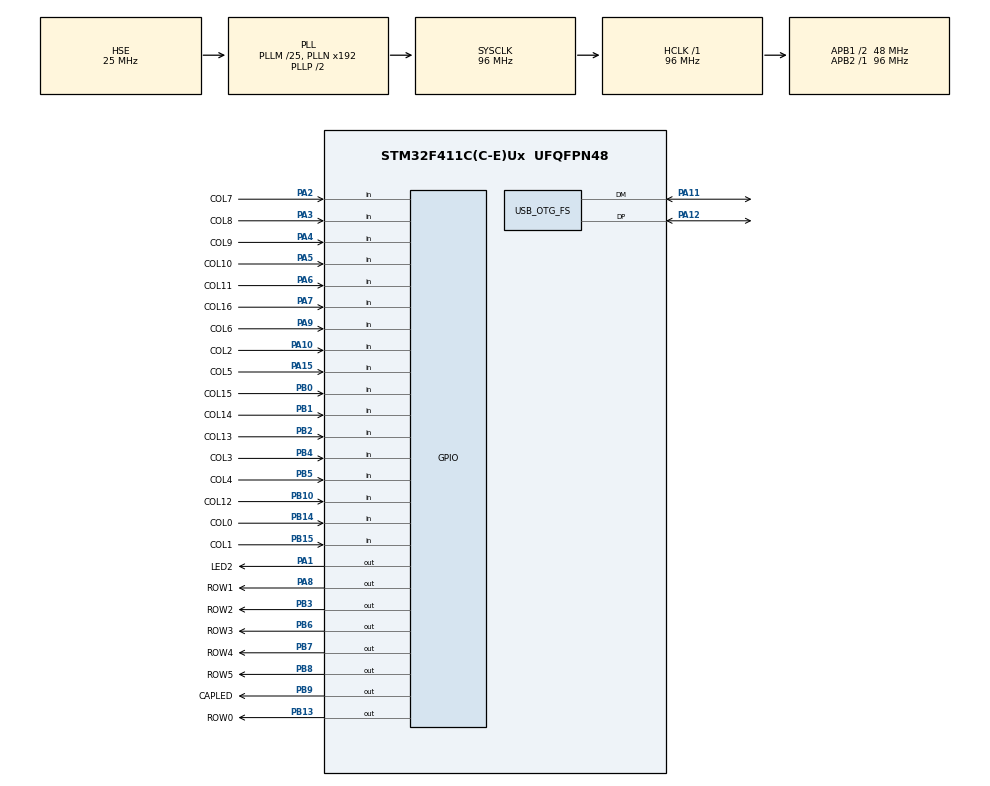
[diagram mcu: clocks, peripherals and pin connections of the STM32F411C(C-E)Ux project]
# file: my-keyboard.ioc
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Mcu.Family=STM32F4
Mcu.Name=STM32F411C(C-E)Ux
Mcu.Package=UFQFPN48
NVIC.OTG_FS_IRQn=true\:0\:0\:false\:false\:true\:false\:true
NVIC.PriorityGroup=NVIC_PRIORITYGROUP_4
PA1.GPIO_Label=LED2
PA1.GPIO_PuPd=GPIO_PULLDOWN
PA1.Signal=GPIO_Output
PA10.GPIO_Label=COL2
PA10.GPIO_PuPd=GPIO_PULLDOWN
PA10.Signal=GPIO_Input
PA11.Mode=Device_Only
PA11.Signal=USB_OTG_FS_DM
PA12.Mode=Device_Only
PA12.Signal=USB_OTG_FS_DP
PA13.Mode=Serial_Wire
PA13.Signal=SYS_JTMS-SWDIO
PA14.Mode=Serial_Wire
PA14.Signal=SYS_JTCK-SWCLK
PA15.GPIO_Label=COL5
PA15.GPIO_PuPd=GPIO_PULLDOWN
PA15.Signal=GPIO_Input
PA2.GPIO_Label=COL7
PA2.GPIO_PuPd=GPIO_PULLDOWN
PA2.Signal=GPIO_Input
PA3.GPIO_Label=COL8
PA3.GPIO_PuPd=GPIO_PULLDOWN
PA3.Signal=GPIO_Input
PA4.GPIO_Label=COL9
PA4.GPIO_PuPd=GPIO_PULLDOWN
PA4.Signal=GPIO_Input
PA5.GPIO_Label=COL10
PA5.GPIO_PuPd=GPIO_PULLDOWN
PA5.Signal=GPIO_Input
PA6.GPIO_Label=COL11
PA6.GPIO_PuPd=GPIO_PULLDOWN
PA6.Signal=GPIO_Input
PA7.GPIO_Label=COL16
PA7.GPIO_PuPd=GPIO_PULLDOWN
PA7.Signal=GPIO_Input
PA8.GPIO_Label=ROW1
PA8.GPIO_PuPd=GPIO_PULLDOWN
PA8.Signal=GPIO_Output
PA9.GPIO_Label=COL6
PA9.GPIO_PuPd=GPIO_PULLDOWN
PA9.Signal=GPIO_Input
PB0.GPIO_Label=COL15
PB0.GPIO_PuPd=GPIO_PULLDOWN
PB0.Signal=GPIO_Input
PB1.GPIO_Label=COL14
PB1.GPIO_PuPd=GPIO_PULLDOWN
PB1.Signal=GPIO_Input
PB10.GPIO_Label=COL12
PB10.GPIO_PuPd=GPIO_PULLDOWN
PB10.Signal=GPIO_Input
PB13.GPIO_Label=ROW0
PB13.GPIO_PuPd=GPIO_PULLDOWN
PB13.Signal=GPIO_Output
PB14.GPIO_Label=COL0
PB14.GPIO_PuPd=GPIO_PULLDOWN
PB14.Signal=GPIO_Input
PB15.GPIO_Label=COL1
PB15.GPIO_PuPd=GPIO_PULLDOWN
PB15.Signal=GPIO_Input
PB2.GPIO_Label=COL13
PB2.GPIO_PuPd=GPIO_PULLDOWN
PB2.Signal=GPIO_Input
PB3.GPIO_Label=ROW2
PB3.GPIO_PuPd=GPIO_PULLDOWN
PB3.Signal=GPIO_Output
PB4.GPIO_Label=COL3
PB4.GPIO_PuPd=GPIO_PULLDOWN
PB4.Signal=GPIO_Input
PB5.GPIO_Label=COL4
PB5.GPIO_PuPd=GPIO_PULLDOWN
PB5.Signal=GPIO_Input
PB6.GPIO_Label=ROW3
PB6.GPIO_PuPd=GPIO_PULLDOWN
PB6.Signal=GPIO_Output
PB7.GPIO_Label=ROW4
PB7.GPIO_PuPd=GPIO_PULLDOWN
PB7.Signal=GPIO_Output
PB8.GPIO_Label=ROW5
PB8.GPIO_PuPd=GPIO_PULLDOWN
PB8.Signal=GPIO_Output
PB9.GPIO_Label=CAPLED
PB9.GPIO_PuPd=GPIO_PULLDOWN
PB9.Signal=GPIO_Output
PH0\ -\ OSC_IN.Mode=HSE-External-Oscillator
PH0\ -\ OSC_IN.Signal=RCC_OSC_IN
PH1\ -\ OSC_OUT.Mode=HSE-External-Oscillator
PH1\ -\ OSC_OUT.Signal=RCC_OSC_OUT
ProjectManager.HeapSize=0x400
ProjectManager.StackSize=0x400
ProjectManager.TargetToolchain=STM32CubeIDE
RCC.48MHZClocksFreq_Value=48000000
RCC.AHBFreq_Value=96000000
RCC.APB1CLKDivider=RCC_HCLK_DIV2
RCC.APB1Freq_Value=48000000
RCC.APB1TimFreq_Value=96000000
RCC.APB2Freq_Value=96000000
RCC.APB2TimFreq_Value=96000000
RCC.CortexFreq_Value=96000000
RCC.HCLKFreq_Value=96000000
RCC.HSE_VALUE=25000000
RCC.HSI_VALUE=16000000
RCC.LSE_VALUE=32768
RCC.PLLM=25
RCC.SYSCLKFreq_VALUE=96000000
RCC.SYSCLKSource=RCC_SYSCLKSOURCE_PLLCLK
RCC.VCOOutputFreq_Value=192000000
USB_DEVICE.CLASS_NAME_FS=HID
USB_DEVICE.VirtualMode=Hid
USB_DEVICE.VirtualModeFS=Hid_FS
USB_OTG_FS.VirtualMode=Device_Only
VP_USB_DEVICE_VS_USB_DEVICE_HID_FS.Mode=HID_FS
board=custom

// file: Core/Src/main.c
/* USER CODE BEGIN Header */
/**
  ******************************************************************************
  * @file           : main.c
  * @brief          : Main program body
  ******************************************************************************
  * @attention
  *
  * <h2><center>&copy; Copyright (c) 2020 STMicroelectronics.
  * All rights reserved.</center></h2>
  *
  * This software component is licensed by ST under BSD 3-Clause license,
  * the "License"; You may not use this file except in compliance with the
  * License. You may obtain a copy of the License at:
  *                        opensource.org/licenses/BSD-3-Clause
  *
  ******************************************************************************
  */
/* USER CODE END Header */

#include "main.h"
#include "usb_device.h"
#include "gpio.h"

/* USER CODE BEGIN Includes */
#include "usbd_hid.h"
#include "keyboard.h"
#include "matrix.h"
/* USER CODE END Includes */

/* USER CODE BEGIN PV */
extern USBD_HandleTypeDef hUsbDeviceFS;
/* USER CODE END PV */

void SystemClock_Config(void);

int main(void)
{

  /* MCU Configuration--------------------------------------------------------*/

  /* Reset of all peripherals, Initializes the Flash interface and the Systick. */
  HAL_Init();

  /* Configure the system clock */
  SystemClock_Config();

  /* Initialize all configured peripherals */
  MX_GPIO_Init();
  MX_USB_DEVICE_Init();
  /* USER CODE BEGIN 2 */
  keyboard_init();
  /* USER CODE END 2 */

  /* Infinite loop */
  while (1)
  {

    /* USER CODE BEGIN 3 */

	  keyboard_task();
  }
  /* USER CODE END 3 */
}

void SystemClock_Config(void)
{
  RCC_OscInitTypeDef RCC_OscInitStruct = {0};
  RCC_ClkInitTypeDef RCC_ClkInitStruct = {0};

  /** Configure the main internal regulator output voltage
  */
  __HAL_RCC_PWR_CLK_ENABLE();
  __HAL_PWR_VOLTAGESCALING_CONFIG(PWR_REGULATOR_VOLTAGE_SCALE1);
  /** Initializes the CPU, AHB and APB busses clocks
  */
  RCC_OscInitStruct.OscillatorType = RCC_OSCILLATORTYPE_HSE;
  RCC_OscInitStruct.HSEState = RCC_HSE_ON;
  RCC_OscInitStruct.PLL.PLLState = RCC_PLL_ON;
  RCC_OscInitStruct.PLL.PLLSource = RCC_PLLSOURCE_HSE;
  RCC_OscInitStruct.PLL.PLLM = 25;
  RCC_OscInitStruct.PLL.PLLN = 192;
  RCC_OscInitStruct.PLL.PLLP = RCC_PLLP_DIV2;
  RCC_OscInitStruct.PLL.PLLQ = 4;
  if (HAL_RCC_OscConfig(&RCC_OscInitStruct) != HAL_OK)
  {
    Error_Handler();
  }
  /** Initializes the CPU, AHB and APB busses clocks
  */
  RCC_ClkInitStruct.ClockType = RCC_CLOCKTYPE_HCLK|RCC_CLOCKTYPE_SYSCLK
                              |RCC_CLOCKTYPE_PCLK1|RCC_CLOCKTYPE_PCLK2;
  RCC_ClkInitStruct.SYSCLKSource = RCC_SYSCLKSOURCE_PLLCLK;
  RCC_ClkInitStruct.AHBCLKDivider = RCC_SYSCLK_DIV1;
  RCC_ClkInitStruct.APB1CLKDivider = RCC_HCLK_DIV2;
  RCC_ClkInitStruct.APB2CLKDivider = RCC_HCLK_DIV1;

  if (HAL_RCC_ClockConfig(&RCC_ClkInitStruct, FLASH_LATENCY_3) != HAL_OK)
  {
    Error_Handler();
  }
}

void Error_Handler(void)
{
}

/************************ (C) COPYRIGHT STMicroelectronics *****END OF FILE****/
